AUTOSAR XML (schema 4-0-3)
standard types defined: Boolean, UInt16, UInt32
package /AUTOSAR_Platform/DataConstrs
  range DC_Boolean: raw 0..1
  range DC_UInt16: raw 0..65535
package /PATAC/MSM/ComponentTypes
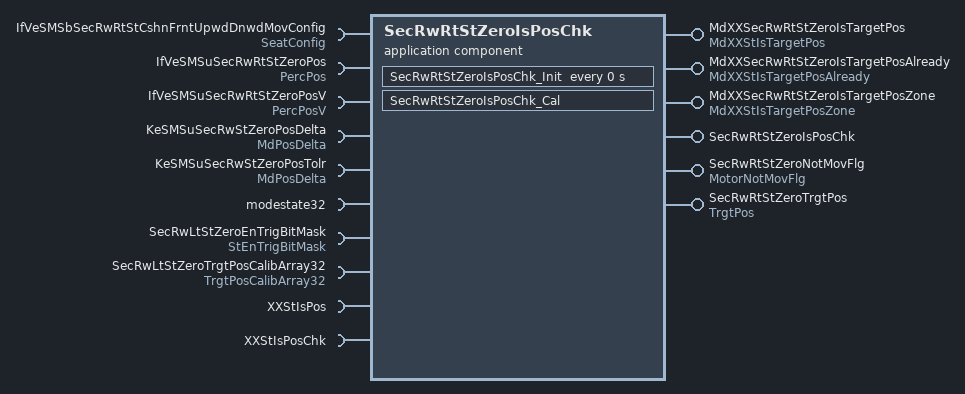
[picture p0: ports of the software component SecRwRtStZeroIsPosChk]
  application sw component type SecRwRtStZeroIsPosChk
    6 x provide port:
      MdXXSecRwRtStZeroIsTargetPos: nonqueued-sender-com-spec=data-element=MdXXStIsTargetPos/Val, provided-interface=MdXXStIsTargetPos
      MdXXSecRwRtStZeroIsTargetPosAlready: nonqueued-sender-com-spec=data-element=MdXXStIsTargetPosAlready/Val, provided-interface=MdXXStIsTargetPosAlready
      MdXXSecRwRtStZeroIsTargetPosZone: nonqueued-sender-com-spec{data-element=MdXXStIsTargetPosZone/Val, init-value=0}, provided-interface=MdXXStIsTargetPosZone
      SecRwRtStZeroIsPosChk: server-com-spec{operation=SecRwRtStZeroIsPosChk/Cal, queue-length=1}, provided-interface=SecRwRtStZeroIsPosChk
      SecRwRtStZeroNotMovFlg: nonqueued-sender-com-spec{data-element=MotorNotMovFlg/Val, init-value=0}, provided-interface=MotorNotMovFlg
      SecRwRtStZeroTrgtPos: nonqueued-sender-com-spec{data-element=TrgtPos/Val, init-value=4095}, provided-interface=TrgtPos
    10 x require port:
      IfVeSMSbSecRwRtStCshnFrntUpwdDnwdMovConfig: nonqueued-receiver-com-spec{data-element=SeatConfig/Val, filter=data-filter-type=ALWAYS, init-value=0}, required-interface=SeatConfig
      IfVeSMSuSecRwRtStZeroPos: nonqueued-receiver-com-spec{data-element=PercPos/Val, filter=data-filter-type=ALWAYS, init-value=0}, required-interface=PercPos
      IfVeSMSuSecRwRtStZeroPosV: nonqueued-receiver-com-spec{data-element=PercPosV/Val, filter=data-filter-type=ALWAYS, init-value=0}, required-interface=PercPosV
      KeSMSuSecRwStZeroPosDelta: parameter-require-com-spec{init-value=150, parameter=Val}, required-interface=MdPosDelta
      KeSMSuSecRwStZeroPosTolr: parameter-require-com-spec{init-value=150, parameter=Val}, required-interface=MdPosDelta
      modestate32: nonqueued-receiver-com-spec{data-element=modestate32/Val, filter=data-filter-type=ALWAYS, init-value=0}, required-interface=modestate32
      SecRwLtStZeroEnTrigBitMask: nonqueued-receiver-com-spec{data-element=StEnTrigBitMask/Val, filter=data-filter-type=ALWAYS, init-value=0}, required-interface=StEnTrigBitMask
      SecRwLtStZeroTrgtPosCalibArray32: nonqueued-receiver-com-spec{data-element=TrgtPosArray32, filter=data-filter-type=ALWAYS, init-value=96 x 4095}, required-interface=TrgtPosCalibArray32
      XXStIsPos: client-com-spec=Get, required-interface=XXStIsPos
      XXStIsPosChk: client-com-spec=XXStIsPosChk/Cal, required-interface=XXStIsPosChk
    behavior SecRwRtStZeroIsPosChk_InternalBehavior
      operation invoked event OIT_SecRwRtStZeroIsPosChk_Cal_SecRwRtStZeroIsPosChk_Cal: start-on-event=SecRwRtStZeroIsPosChk_Cal, operation=SecRwRtStZeroIsPosChk.Cal
      timing event SecRwRtStZeroIsPosChk_InitEvent: start-on-event=SecRwRtStZeroIsPosChk_Init, period=0
      runnable SecRwRtStZeroIsPosChk_Cal
        data-receive-point-by-arguments:
          6 x access:
            REC_IfVeSMSbSecRwRtStCshnFrntUpwdDnwdMovConfig_Val: accessed-variable=IfVeSMSbSecRwRtStCshnFrntUpwdDnwdMovConfig.Val
            REC_IfVeSMSuSecRwRtStZeroPos_Val: accessed-variable=IfVeSMSuSecRwRtStZeroPos.Val
            REC_IfVeSMSuSecRwRtStZeroPosV_Val: accessed-variable=IfVeSMSuSecRwRtStZeroPosV.Val
            REC_modestate32_Val: accessed-variable=modestate32.Val
            REC_SecRwLtStZeroEnTrigBitMask_Val: accessed-variable=SecRwLtStZeroEnTrigBitMask.Val
            REC_SecRwLtStZeroTrgtPosCalibArray32_TrgtPosArray32: accessed-variable=SecRwLtStZeroTrgtPosCalibArray32.TrgtPosArray32
        data-send-points:
          5 x access:
            SEND_MdXXSecRwRtStZeroIsTargetPos_Val: accessed-variable=MdXXSecRwRtStZeroIsTargetPos.Val
            SEND_MdXXSecRwRtStZeroIsTargetPosAlready_Val: accessed-variable=MdXXSecRwRtStZeroIsTargetPosAlready.Val
            SEND_MdXXSecRwRtStZeroIsTargetPosZone_Val: accessed-variable=MdXXSecRwRtStZeroIsTargetPosZone.Val
            SEND_SecRwRtStZeroNotMovFlg_Val: accessed-variable=SecRwRtStZeroNotMovFlg.Val
            SEND_SecRwRtStZeroTrgtPos_Val: accessed-variable=SecRwRtStZeroTrgtPos.Val
        parameter access PA_KeSMSuSecRwStZeroPosDelta_Val: accessed-parameter=KeSMSuSecRwStZeroPosDelta.Val
        parameter access PA_KeSMSuSecRwStZeroPosTolr_Val: accessed-parameter=KeSMSuSecRwStZeroPosTolr.Val
        sync call SC_XXStIsPos_Get: operation=XXStIsPos.Get, timeout=0
        sync call SC_XXStIsPosChk_Cal: operation=XXStIsPosChk.Cal, timeout=0
      runnable SecRwRtStZeroIsPosChk_Init
        parameter access PA_KeSMSuSecRwStZeroPosDelta_Val: accessed-parameter=KeSMSuSecRwStZeroPosDelta.Val
        parameter access PA_KeSMSuSecRwStZeroPosTolr_Val: accessed-parameter=KeSMSuSecRwStZeroPosTolr.Val
  swc implementation SecRwRtStZeroIsPosChk_Implementation: behavior=SecRwRtStZeroIsPosChk_InternalBehavior
    code-descriptors:
      code Default: artifact-descriptors=autosar-engineering-object={short-label=Default, category=SWSRC}
package /PATAC/MSM/ModeAdjust/CalPortInterface
  parameter interface MdPosDelta
    parameter data prototype Val: sw-calibration-access=READ-WRITE, type=UInt16
package /PATAC/MSM/ModeAdjust/DataType
  impl type TrgtPosCalibArray: category=ARRAY, sw-calibration-access=READ-ONLY, type-emitter=RTE  # 0:pos 1:max 2:min
    element Element: array-size=3, array-size-semantics=FIXED-SIZE, implementation-data-type=UInt16, invalid-value=0
  impl type TrgtPosCalibArray32: category=ARRAY, sw-calibration-access=READ-ONLY, type-emitter=RTE  # 0:pos 1:max 2:min
    element Element: array-size=96, array-size-semantics=FIXED-SIZE, implementation-data-type=UInt16, invalid-value=0
package /PATAC/MSM/ModeAdjust/PortInterface
  client server interface SecRwRtStZeroIsPosChk
    operation Cal
  client server interface XXStIsPos
    operation Get
      8 x arg, all with server-argument-impl-policy=USE-ARGUMENT-TYPE:
        PosV: type=DataTypes/Boolean, direction=IN
        Pos: type=UInt16, direction=IN
        CalibArray: type=TrgtPosCalibArray, direction=IN
        Delta: type=UInt16, direction=IN
        Tolr: type=UInt16, direction=IN
        IsPos: type=DataTypes/Boolean, direction=OUT
        IsPosZone: type=DataTypes/Boolean, direction=OUT
        IsPosAlready: type=DataTypes/Boolean, direction=OUT
  client server interface XXStIsPosChk
    operation Cal
      13 x arg, all with server-argument-impl-policy=USE-ARGUMENT-TYPE:
        MdCalibArray32: type=TrgtPosCalibArray32, direction=IN
        Pos: type=UInt16, direction=IN
        PosV: type=DataTypes/Boolean, direction=IN
        MovConfig: type=DataTypes/Boolean, direction=IN
        modestate32: type=UInt32, direction=IN
        IsPos: type=UInt32, direction=OUT
        IsPosAlready: type=UInt32, direction=OUT
        IsPosZone: type=UInt32, direction=OUT
        NotMovFlg: type=DataTypes/Boolean, direction=OUT
        StTrgtPos: type=UInt16, direction=OUT
        PosDelta: type=UInt16, direction=IN
        PosTolr: type=UInt16, direction=IN
        StBitMask: type=UInt32, direction=IN
  9 x sender receiver interface:
    MdXXStIsTargetPos: invalidation-policy{data-element=MdXXStIsTargetPos/Val, handle-invalid=DONT-INVALIDATE}
      data Val: type=UInt32
    MdXXStIsTargetPosAlready: invalidation-policy{data-element=MdXXStIsTargetPosAlready/Val, handle-invalid=DONT-INVALIDATE}
      data Val: type=UInt32
    MdXXStIsTargetPosZone: invalidation-policy{data-element=MdXXStIsTargetPosZone/Val, handle-invalid=DONT-INVALIDATE}
      data Val: type=UInt32
    modestate32: invalidation-policy{data-element=modestate32/Val, handle-invalid=DONT-INVALIDATE}
      data Val: type=UInt32
    MotorNotMovFlg: invalidation-policy{data-element=MotorNotMovFlg/Val, handle-invalid=DONT-INVALIDATE}
      data Val: type=Implementation/Boolean
    PercPos: invalidation-policy{data-element=PercPos/Val, handle-invalid=DONT-INVALIDATE}
      data Val: type=UInt16
    PercPosV: invalidation-policy{data-element=PercPosV/Val, handle-invalid=DONT-INVALIDATE}
      data Val: type=Implementation/Boolean
    StEnTrigBitMask: invalidation-policy{data-element=StEnTrigBitMask/Val, handle-invalid=DONT-INVALIDATE}
      data Val: type=UInt32
    TrgtPosCalibArray32: invalidation-policy{data-element=TrgtPosArray32, handle-invalid=DONT-INVALIDATE}
      data TrgtPosArray32: type=TrgtPosCalibArray32  # 0:Pos 1:Max 2:Min
package /PATAC/MSM/PortInterfaces
  sender receiver interface SeatConfig: invalidation-policy{data-element=SeatConfig/Val, handle-invalid=DONT-INVALIDATE}
    data Val: type=Implementation/Boolean
  sender receiver interface TrgtPos: invalidation-policy{data-element=TrgtPos/Val, handle-invalid=DONT-INVALIDATE}
    data Val: type=UInt16
